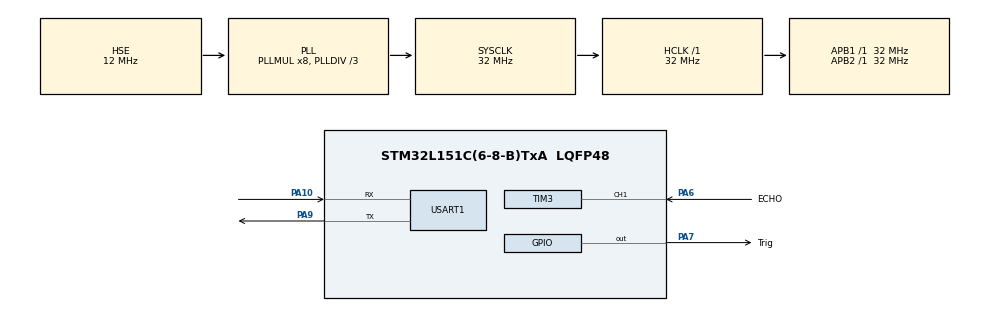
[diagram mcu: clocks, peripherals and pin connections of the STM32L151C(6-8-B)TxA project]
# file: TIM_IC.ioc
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Mcu.Family=STM32L1
Mcu.Name=STM32L151C(6-8-B)TxA
Mcu.Package=LQFP48
NVIC.PriorityGroup=NVIC_PRIORITYGROUP_4
NVIC.TIM3_IRQn=true\:0\:0\:false\:false\:true\:true\:true
PA10.Mode=Asynchronous
PA10.Signal=USART1_RX
PA13.Mode=Serial_Wire
PA13.Signal=SYS_JTMS-SWDIO
PA14.Mode=Serial_Wire
PA14.Signal=SYS_JTCK-SWCLK
PA6.GPIO_Label=ECHO
PA6.GPIO_PuPd=GPIO_PULLDOWN
PA6.Signal=S_TIM3_CH1
PA7.GPIO_Label=Trig
PA7.Signal=GPIO_Output
PA9.Mode=Asynchronous
PA9.Signal=USART1_TX
PH0-OSC_IN.Mode=HSE-External-Oscillator
PH0-OSC_IN.Signal=RCC_OSC_IN
PH1-OSC_OUT.Mode=HSE-External-Oscillator
PH1-OSC_OUT.Signal=RCC_OSC_OUT
ProjectManager.HeapSize=0x200
ProjectManager.StackSize=0x400
ProjectManager.TargetToolchain=MDK-ARM V5.27
RCC.48MHZClocksFreq_Value=48000000
RCC.AHBFreq_Value=32000000
RCC.APB1Freq_Value=32000000
RCC.APB1TimFreq_Value=32000000
RCC.APB2Freq_Value=32000000
RCC.APB2TimFreq_Value=32000000
RCC.HCLKFreq_Value=32000000
RCC.HSE_VALUE=12000000
RCC.HSI_VALUE=16000000
RCC.LSE_VALUE=32768
RCC.MSI_VALUE=2097000
RCC.PLLDIV=RCC_PLL_DIV3
RCC.PLLMUL=RCC_PLL_MUL8
RCC.PLLSourceVirtual=RCC_PLLSOURCE_HSE
RCC.SYSCLKFreq_VALUE=32000000
RCC.SYSCLKSource=RCC_SYSCLKSOURCE_PLLCLK
RCC.VCOOutputFreq_Value=96000000
SH.S_TIM3_CH1.0=TIM3_CH1,Input_Capture1_from_TI1
TIM3.AutoReloadPreload=TIM_AUTORELOAD_PRELOAD_ENABLE
TIM3.Channel-Input_Capture1_from_TI1=TIM_CHANNEL_1
TIM3.Prescaler=32-1
USART1.VirtualMode=VM_ASYNC
VP_TIM3_VS_ClockSourceINT.Mode=Internal
board=custom

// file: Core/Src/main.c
/* USER CODE BEGIN Header */
/**
  ******************************************************************************
  * @file           : main.c
  * @brief          : Main program body
  ******************************************************************************
  * @attention
  *
  * <h2><center>&copy; Copyright (c) 2020 STMicroelectronics.
  * All rights reserved.</center></h2>
  *
  * This software component is licensed by ST under BSD 3-Clause license,
  * the "License"; You may not use this file except in compliance with the
  * License. You may obtain a copy of the License at:
  *                        opensource.org/licenses/BSD-3-Clause
  *
  ******************************************************************************
  */
/* USER CODE END Header */
#include "main.h"
#include "tim.h"
#include "usart.h"
#include "gpio.h"

void SystemClock_Config(void);

int main(void)
{

  /* MCU Configuration--------------------------------------------------------*/

  /* Reset of all peripherals, Initializes the Flash interface and the Systick. */
  HAL_Init();

  /* Configure the system clock */
  SystemClock_Config();

  /* Initialize all configured peripherals */
  MX_GPIO_Init();
  MX_USART1_UART_Init();
  MX_TIM3_Init();

  /* Infinite loop */
  /* USER CODE BEGIN WHILE */
  while (1)
  {
		if(CapValReady == 1)
		{
			//25.5cm-350cm
			USData = CapVal * 34000/1000000/2;//声速34000cm/s TIM3Freq：1000000Hz
			if(USData <= 350 && USData >= 25.5)
			{
				printf("US:%.2fcm\r\n",USData);
			}
			__HAL_TIM_DISABLE(&htim3);
			HAL_Delay(500);
			__HAL_TIM_SET_COUNTER(&htim3,0);//设置定时器3计数值为0
			__HAL_TIM_ENABLE(&htim3);
			CapValReady = 0;
			USTrig();
			HAL_TIM_IC_Start_IT(&htim3,TIM_CHANNEL_1);//定时器3通道1输入捕获使能
		}
    /* USER CODE END WHILE */

  }
}

void SystemClock_Config(void)
{
  RCC_OscInitTypeDef RCC_OscInitStruct = {0};
  RCC_ClkInitTypeDef RCC_ClkInitStruct = {0};

  /** Configure the main internal regulator output voltage
  */
  __HAL_PWR_VOLTAGESCALING_CONFIG(PWR_REGULATOR_VOLTAGE_SCALE1);
  /** Initializes the RCC Oscillators according to the specified parameters
  * in the RCC_OscInitTypeDef structure.
  */
  RCC_OscInitStruct.OscillatorType = RCC_OSCILLATORTYPE_HSE;
  RCC_OscInitStruct.HSEState = RCC_HSE_ON;
  RCC_OscInitStruct.PLL.PLLState = RCC_PLL_ON;
  RCC_OscInitStruct.PLL.PLLSource = RCC_PLLSOURCE_HSE;
  RCC_OscInitStruct.PLL.PLLMUL = RCC_PLL_MUL8;
  RCC_OscInitStruct.PLL.PLLDIV = RCC_PLL_DIV3;
  if (HAL_RCC_OscConfig(&RCC_OscInitStruct) != HAL_OK)
  {
    Error_Handler();
  }
  /** Initializes the CPU, AHB and APB buses clocks
  */
  RCC_ClkInitStruct.ClockType = RCC_CLOCKTYPE_HCLK|RCC_CLOCKTYPE_SYSCLK
                              |RCC_CLOCKTYPE_PCLK1|RCC_CLOCKTYPE_PCLK2;
  RCC_ClkInitStruct.SYSCLKSource = RCC_SYSCLKSOURCE_PLLCLK;
  RCC_ClkInitStruct.AHBCLKDivider = RCC_SYSCLK_DIV1;
  RCC_ClkInitStruct.APB1CLKDivider = RCC_HCLK_DIV1;
  RCC_ClkInitStruct.APB2CLKDivider = RCC_HCLK_DIV1;

  if (HAL_RCC_ClockConfig(&RCC_ClkInitStruct, FLASH_LATENCY_1) != HAL_OK)
  {
    Error_Handler();
  }
}

void Error_Handler(void)
{
}

/************************ (C) COPYRIGHT STMicroelectronics *****END OF FILE****/
